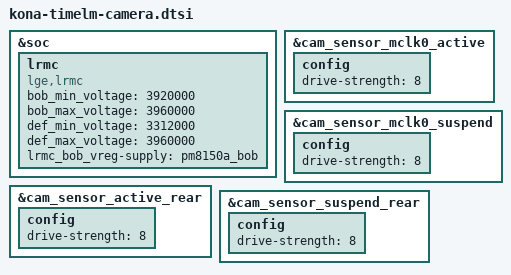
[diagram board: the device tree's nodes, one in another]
// SPDX-License-Identifier: GPL-2.0-only
/*
 * timelm: camera parts shared by every board revision.
 *
 * The sensors, actuators, OIS, eeproms and flash differ per revision and
 * live in kona-timelm-camera_{rev0,reva,revb}.dtsi, included by the
 * kona-timelm_*_rev-*.dts leaves as in the LG 4.19 overlays.
 *
 * lge,lrmc from LG kona-timelm_common-pm.dtsi (BOB boost while the flash
 * fires high; driver in camera.ko).
 */

&soc {
	lrmc {
		compatible = "lge,lrmc";
		bob_min_voltage		= <3920000>;
		bob_max_voltage		= <3960000>;
		def_min_voltage		= <3312000>;
		def_max_voltage		= <3960000>;
		lrmc_bob_vreg-supply = <&pm8150a_bob>;
	};
};

/*
 * LG's kona-pinctrl.dtsi drives the rear (MCLK0 / gpio93 reset) pins at
 * 8 mA; the 5.15 QC kona-pinctrl.dtsi has 2 mA (v60-live.dts: 8 mA).
 */
&cam_sensor_mclk0_active {
	config {
		drive-strength = <8>; /* 8 MA */
	};
};

&cam_sensor_mclk0_suspend {
	config {
		drive-strength = <8>; /* 8 MA */
	};
};

&cam_sensor_active_rear {
	config {
		drive-strength = <8>; /* 8 MA */
	};
};

&cam_sensor_suspend_rear {
	config {
		drive-strength = <8>; /* 8 MA */
	};
};
